# iqn_ail register map
Vendor: Texas Instruments
Registers are 32-bit, read-only, no defined reset value unless marked. A register's access mark holds for its fields unless they carry their own. Offsets are as the file gives them; [hi:lo] are bit positions.

## IQN_AIL (part 4 of 5)
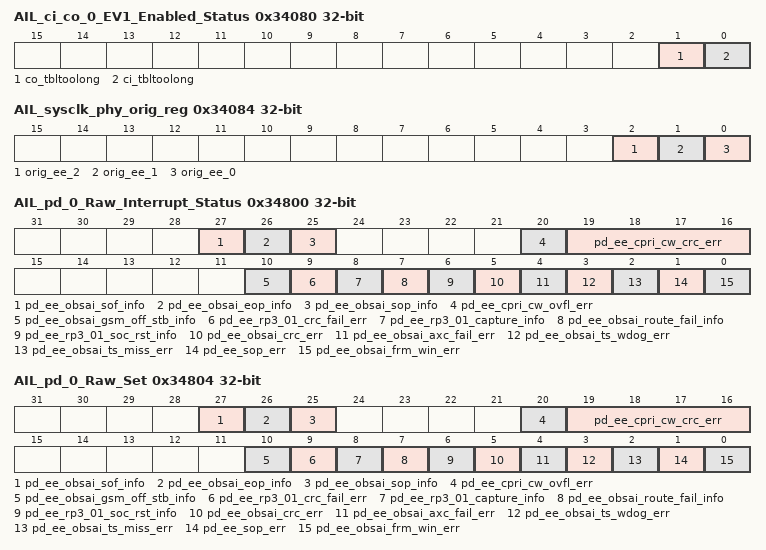
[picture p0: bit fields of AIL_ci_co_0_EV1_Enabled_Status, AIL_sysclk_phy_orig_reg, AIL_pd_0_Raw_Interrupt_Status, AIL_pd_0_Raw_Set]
0x34080 AIL_ci_co_0_EV1_Enabled_Status — (1 of 1, stride 0)
  [1] co_tbltoolong — AND-ed raw_status bits with the corresponding bit in the intr1_status register. Read only.
  [0] ci_tbltoolong — AND-ed raw_status bits with the corresponding bit in the intr1_status register. Read only.
0x34084 AIL_sysclk_phy_orig_reg — (1 of 1, stride 0)
  [2] orig_ee_2 — If set a bit is set in the ci_co_0 register.
  [1] orig_ee_1 — If set a bit is set in the rt_tm_0 register.
  [0] orig_ee_0 — If set a bit is set in the rm_0 register.
0x34800 AIL_pd_0_Raw_Interrupt_Status — (1 of 1, stride 0)
  [27] pd_ee_obsai_sof_info — OBSAI, on any channel, an sof occurred from the PD.
  [26] pd_ee_obsai_eop_info — OBSAI, on any channel, an eop occurred from the PD.
  [25] pd_ee_obsai_sop_info — OBSAI, on any channel, an sop occurred from the PD.
  [20] pd_ee_cpri_cw_ovfl_err — The CPRI CW Fifo for the channel has overflowed, indicating that it was not serviced fast enough.
  [19:16] pd_ee_cpri_cw_crc_err — When CPRI CW CRC checks are enabled, a CRC was received which did not match the calculated CRC. CRC failure could be caused by SERDES bit error
  [10] pd_ee_obsai_gsm_off_stb_info — OBSAI, a gsm off strobe was received for a channel.
  [9] pd_ee_rp3_01_crc_fail_err — OBSAI, a remote rp3-01 message was recieved but the CRC failed for the message.
  [8] pd_ee_rp3_01_capture_info — OBSAI, a remote rp3-01 message was received as determined by the lut table.
  [7] pd_ee_obsai_route_fail_info — OBSAI, a received message failed to match entries for addr and type in the lut table.
  [6] pd_ee_rp3_01_soc_rst_info — OBSAI, received a remote RP3-01 message controlling the entire SOC to perform a HW reset. AIL port will strobe, Must be enabled at higher layers of SOC to perform actual RESET (similar function exists for CPRI, but controlled via PHY_RM)
  [5] pd_ee_obsai_crc_err — OBSAI, ctrl packet crc failure, pkt marked as bad
  [4] pd_ee_obsai_axc_fail_err — OBSAI, unrecoverable ts or wdog error, chan restart. Caused by missing or extra OBSAI messages. (OBSAI time stamp prediction failure)
  [3] pd_ee_obsai_ts_wdog_err — OBSAI, watch dog timed out before chan received OBSAI msg.
  [2] pd_ee_obsai_ts_miss_err — OBSAI, single missing timestamp, sometimes recoverable
  [1] pd_ee_sop_err — Received a second SOP without an EOP in between. Valid for OBSAIpacket types and CPRI 4B/5B encoding (PD_Frame)
  [0] pd_ee_obsai_frm_win_err — OBSAI timestamp failed timing window test. Wrap of the PD_Frame Counters did not predict a Radio Frame Boundary consistent with TS=0 falling within the reception timing window.
0x34804 AIL_pd_0_Raw_Set wo — (1 of 1, stride 0)
  [27] pd_ee_obsai_sof_info — Sets the corresponding bit in the raw_status register when set. Write only, self-clears.
  [26] pd_ee_obsai_eop_info — Sets the corresponding bit in the raw_status register when set. Write only, self-clears.
  [25] pd_ee_obsai_sop_info — Sets the corresponding bit in the raw_status register when set. Write only, self-clears.
  [20] pd_ee_cpri_cw_ovfl_err — Sets the corresponding bit in the raw_status register when set. Write only, self-clears.
  [19:16] pd_ee_cpri_cw_crc_err — Sets the corresponding bit in the raw_status register when set. Write only, self-clears.
  [10] pd_ee_obsai_gsm_off_stb_info — Sets the corresponding bit in the raw_status register when set. Write only, self-clears.
  [9] pd_ee_rp3_01_crc_fail_err — Sets the corresponding bit in the raw_status register when set. Write only, self-clears.
  [8] pd_ee_rp3_01_capture_info — Sets the corresponding bit in the raw_status register when set. Write only, self-clears.
  [7] pd_ee_obsai_route_fail_info — Sets the corresponding bit in the raw_status register when set. Write only, self-clears.
  [6] pd_ee_rp3_01_soc_rst_info — Sets the corresponding bit in the raw_status register when set. Write only, self-clears.
  [5] pd_ee_obsai_crc_err — Sets the corresponding bit in the raw_status register when set. Write only, self-clears.
  [4] pd_ee_obsai_axc_fail_err — Sets the corresponding bit in the raw_status register when set. Write only, self-clears.
  [3] pd_ee_obsai_ts_wdog_err — Sets the corresponding bit in the raw_status register when set. Write only, self-clears.
  [2] pd_ee_obsai_ts_miss_err — Sets the corresponding bit in the raw_status register when set. Write only, self-clears.
  [1] pd_ee_sop_err — Sets the corresponding bit in the raw_status register when set. Write only, self-clears.
  [0] pd_ee_obsai_frm_win_err — Sets the corresponding bit in the raw_status register when set. Write only, self-clears.
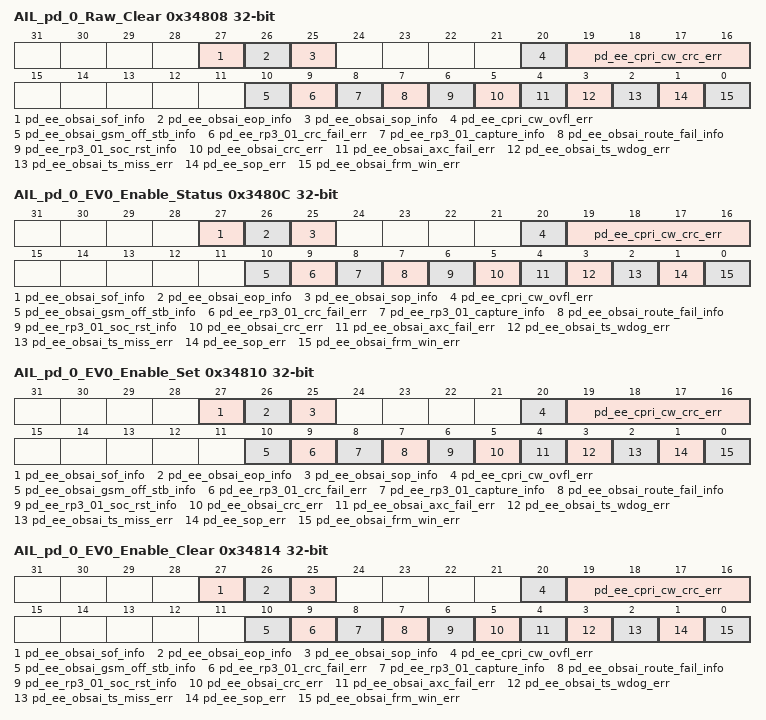
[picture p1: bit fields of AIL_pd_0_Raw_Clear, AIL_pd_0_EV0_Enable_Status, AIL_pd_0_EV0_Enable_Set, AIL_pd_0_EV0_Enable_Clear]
0x34808 AIL_pd_0_Raw_Clear wo — (1 of 1, stride 0)
  [27] pd_ee_obsai_sof_info — Clears the corresponding bit in the raw_status register when set. Write only, self-clears.
  [26] pd_ee_obsai_eop_info — Clears the corresponding bit in the raw_status register when set. Write only, self-clears.
  [25] pd_ee_obsai_sop_info — Clears the corresponding bit in the raw_status register when set. Write only, self-clears.
  [20] pd_ee_cpri_cw_ovfl_err — Clears the corresponding bit in the raw_status register when set. Write only, self-clears.
  [19:16] pd_ee_cpri_cw_crc_err — Clears the corresponding bit in the raw_status register when set. Write only, self-clears.
  [10] pd_ee_obsai_gsm_off_stb_info — Clears the corresponding bit in the raw_status register when set. Write only, self-clears.
  [9] pd_ee_rp3_01_crc_fail_err — Clears the corresponding bit in the raw_status register when set. Write only, self-clears.
  [8] pd_ee_rp3_01_capture_info — Clears the corresponding bit in the raw_status register when set. Write only, self-clears.
  [7] pd_ee_obsai_route_fail_info — Clears the corresponding bit in the raw_status register when set. Write only, self-clears.
  [6] pd_ee_rp3_01_soc_rst_info — Clears the corresponding bit in the raw_status register when set. Write only, self-clears.
  [5] pd_ee_obsai_crc_err — Clears the corresponding bit in the raw_status register when set. Write only, self-clears.
  [4] pd_ee_obsai_axc_fail_err — Clears the corresponding bit in the raw_status register when set. Write only, self-clears.
  [3] pd_ee_obsai_ts_wdog_err — Clears the corresponding bit in the raw_status register when set. Write only, self-clears.
  [2] pd_ee_obsai_ts_miss_err — Clears the corresponding bit in the raw_status register when set. Write only, self-clears.
  [1] pd_ee_sop_err — Clears the corresponding bit in the raw_status register when set. Write only, self-clears.
  [0] pd_ee_obsai_frm_win_err — Clears the corresponding bit in the raw_status register when set. Write only, self-clears.
0x3480C AIL_pd_0_EV0_Enable_Status — (1 of 1, stride 0)
  [27] pd_ee_obsai_sof_info — When set allows the corresponding bit in the raw_status register to generate the intr_sts interrupt. Read only.
  [26] pd_ee_obsai_eop_info — When set allows the corresponding bit in the raw_status register to generate the intr_sts interrupt. Read only.
  [25] pd_ee_obsai_sop_info — When set allows the corresponding bit in the raw_status register to generate the intr_sts interrupt. Read only.
  [20] pd_ee_cpri_cw_ovfl_err — When set allows the corresponding bit in the raw_status register to generate the intr_sts interrupt. Read only.
  [19:16] pd_ee_cpri_cw_crc_err — When set allows the corresponding bit in the raw_status register to generate the intr_sts interrupt. Read only.
  [10] pd_ee_obsai_gsm_off_stb_info — When set allows the corresponding bit in the raw_status register to generate the intr_sts interrupt. Read only.
  [9] pd_ee_rp3_01_crc_fail_err — When set allows the corresponding bit in the raw_status register to generate the intr_sts interrupt. Read only.
  [8] pd_ee_rp3_01_capture_info — When set allows the corresponding bit in the raw_status register to generate the intr_sts interrupt. Read only.
  [7] pd_ee_obsai_route_fail_info — When set allows the corresponding bit in the raw_status register to generate the intr_sts interrupt. Read only.
  [6] pd_ee_rp3_01_soc_rst_info — When set allows the corresponding bit in the raw_status register to generate the intr_sts interrupt. Read only.
  [5] pd_ee_obsai_crc_err — When set allows the corresponding bit in the raw_status register to generate the intr_sts interrupt. Read only.
  [4] pd_ee_obsai_axc_fail_err — When set allows the corresponding bit in the raw_status register to generate the intr_sts interrupt. Read only.
  [3] pd_ee_obsai_ts_wdog_err — When set allows the corresponding bit in the raw_status register to generate the intr_sts interrupt. Read only.
  [2] pd_ee_obsai_ts_miss_err — When set allows the corresponding bit in the raw_status register to generate the intr_sts interrupt. Read only.
  [1] pd_ee_sop_err — When set allows the corresponding bit in the raw_status register to generate the intr_sts interrupt. Read only.
  [0] pd_ee_obsai_frm_win_err — When set allows the corresponding bit in the raw_status register to generate the intr_sts interrupt. Read only.
0x34810 AIL_pd_0_EV0_Enable_Set wo — (1 of 1, stride 0)
  [27] pd_ee_obsai_sof_info — Sets the corresponding bit in the enable register when set. Write only, self-clears.
  [26] pd_ee_obsai_eop_info — Sets the corresponding bit in the enable register when set. Write only, self-clears.
  [25] pd_ee_obsai_sop_info — Sets the corresponding bit in the enable register when set. Write only, self-clears.
  [20] pd_ee_cpri_cw_ovfl_err — Sets the corresponding bit in the enable register when set. Write only, self-clears.
  [19:16] pd_ee_cpri_cw_crc_err — Sets the corresponding bit in the enable register when set. Write only, self-clears.
  [10] pd_ee_obsai_gsm_off_stb_info — Sets the corresponding bit in the enable register when set. Write only, self-clears.
  [9] pd_ee_rp3_01_crc_fail_err — Sets the corresponding bit in the enable register when set. Write only, self-clears.
  [8] pd_ee_rp3_01_capture_info — Sets the corresponding bit in the enable register when set. Write only, self-clears.
  [7] pd_ee_obsai_route_fail_info — Sets the corresponding bit in the enable register when set. Write only, self-clears.
  [6] pd_ee_rp3_01_soc_rst_info — Sets the corresponding bit in the enable register when set. Write only, self-clears.
  [5] pd_ee_obsai_crc_err — Sets the corresponding bit in the enable register when set. Write only, self-clears.
  [4] pd_ee_obsai_axc_fail_err — Sets the corresponding bit in the enable register when set. Write only, self-clears.
  [3] pd_ee_obsai_ts_wdog_err — Sets the corresponding bit in the enable register when set. Write only, self-clears.
  [2] pd_ee_obsai_ts_miss_err — Sets the corresponding bit in the enable register when set. Write only, self-clears.
  [1] pd_ee_sop_err — Sets the corresponding bit in the enable register when set. Write only, self-clears.
  [0] pd_ee_obsai_frm_win_err — Sets the corresponding bit in the enable register when set. Write only, self-clears.
0x34814 AIL_pd_0_EV0_Enable_Clear wo — (1 of 1, stride 0)
  [27] pd_ee_obsai_sof_info — Clears the corresponding bit in the enable register when set. Write only, self-clears.
  [26] pd_ee_obsai_eop_info — Clears the corresponding bit in the enable register when set. Write only, self-clears.
  [25] pd_ee_obsai_sop_info — Clears the corresponding bit in the enable register when set. Write only, self-clears.
  [20] pd_ee_cpri_cw_ovfl_err — Clears the corresponding bit in the enable register when set. Write only, self-clears.
  [19:16] pd_ee_cpri_cw_crc_err — Clears the corresponding bit in the enable register when set. Write only, self-clears.
  [10] pd_ee_obsai_gsm_off_stb_info — Clears the corresponding bit in the enable register when set. Write only, self-clears.
  [9] pd_ee_rp3_01_crc_fail_err — Clears the corresponding bit in the enable register when set. Write only, self-clears.
  [8] pd_ee_rp3_01_capture_info — Clears the corresponding bit in the enable register when set. Write only, self-clears.
  [7] pd_ee_obsai_route_fail_info — Clears the corresponding bit in the enable register when set. Write only, self-clears.
  [6] pd_ee_rp3_01_soc_rst_info — Clears the corresponding bit in the enable register when set. Write only, self-clears.
  [5] pd_ee_obsai_crc_err — Clears the corresponding bit in the enable register when set. Write only, self-clears.
  [4] pd_ee_obsai_axc_fail_err — Clears the corresponding bit in the enable register when set. Write only, self-clears.
  [3] pd_ee_obsai_ts_wdog_err — Clears the corresponding bit in the enable register when set. Write only, self-clears.
  [2] pd_ee_obsai_ts_miss_err — Clears the corresponding bit in the enable register when set. Write only, self-clears.
  [1] pd_ee_sop_err — Clears the corresponding bit in the enable register when set. Write only, self-clears.
  [0] pd_ee_obsai_frm_win_err — Clears the corresponding bit in the enable register when set. Write only, self-clears.
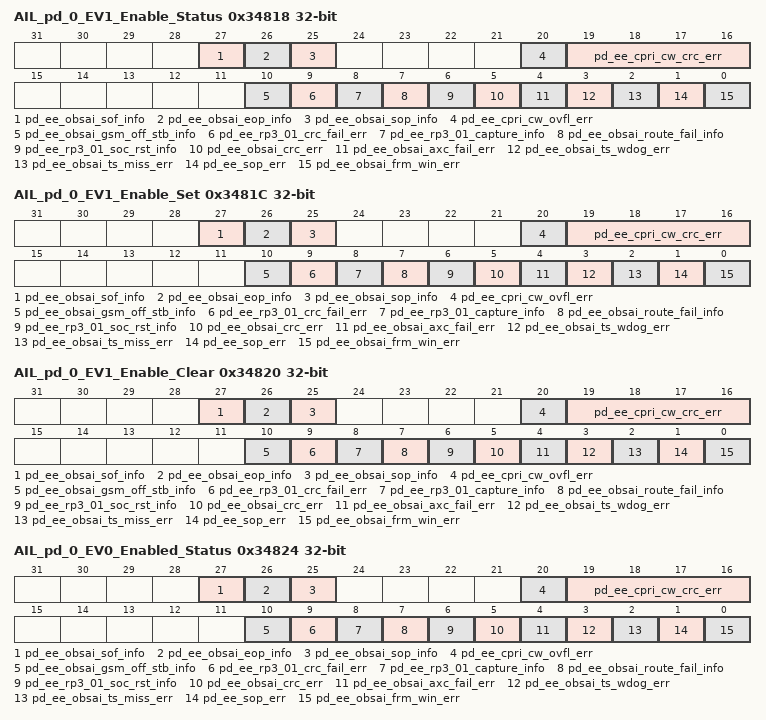
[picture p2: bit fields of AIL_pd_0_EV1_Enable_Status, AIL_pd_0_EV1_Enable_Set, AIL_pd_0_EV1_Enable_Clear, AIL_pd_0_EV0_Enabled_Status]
0x34818 AIL_pd_0_EV1_Enable_Status — (1 of 1, stride 0)
  [27] pd_ee_obsai_sof_info — When set allows the corresponding bit in the raw_status register to generate the intr1_sts interrupt. Read only.
  [26] pd_ee_obsai_eop_info — When set allows the corresponding bit in the raw_status register to generate the intr1_sts interrupt. Read only.
  [25] pd_ee_obsai_sop_info — When set allows the corresponding bit in the raw_status register to generate the intr1_sts interrupt. Read only.
  [20] pd_ee_cpri_cw_ovfl_err — When set allows the corresponding bit in the raw_status register to generate the intr1_sts interrupt. Read only.
  [19:16] pd_ee_cpri_cw_crc_err — When set allows the corresponding bit in the raw_status register to generate the intr1_sts interrupt. Read only.
  [10] pd_ee_obsai_gsm_off_stb_info — When set allows the corresponding bit in the raw_status register to generate the intr1_sts interrupt. Read only.
  [9] pd_ee_rp3_01_crc_fail_err — When set allows the corresponding bit in the raw_status register to generate the intr1_sts interrupt. Read only.
  [8] pd_ee_rp3_01_capture_info — When set allows the corresponding bit in the raw_status register to generate the intr1_sts interrupt. Read only.
  [7] pd_ee_obsai_route_fail_info — When set allows the corresponding bit in the raw_status register to generate the intr1_sts interrupt. Read only.
  [6] pd_ee_rp3_01_soc_rst_info — When set allows the corresponding bit in the raw_status register to generate the intr1_sts interrupt. Read only.
  [5] pd_ee_obsai_crc_err — When set allows the corresponding bit in the raw_status register to generate the intr1_sts interrupt. Read only.
  [4] pd_ee_obsai_axc_fail_err — When set allows the corresponding bit in the raw_status register to generate the intr1_sts interrupt. Read only.
  [3] pd_ee_obsai_ts_wdog_err — When set allows the corresponding bit in the raw_status register to generate the intr1_sts interrupt. Read only.
  [2] pd_ee_obsai_ts_miss_err — When set allows the corresponding bit in the raw_status register to generate the intr1_sts interrupt. Read only.
  [1] pd_ee_sop_err — When set allows the corresponding bit in the raw_status register to generate the intr1_sts interrupt. Read only.
  [0] pd_ee_obsai_frm_win_err — When set allows the corresponding bit in the raw_status register to generate the intr1_sts interrupt. Read only.
0x3481C AIL_pd_0_EV1_Enable_Set wo — (1 of 1, stride 0)
  [27] pd_ee_obsai_sof_info — Sets the corresponding bit in the intr1_status register when set. Write only, self-clears.
  [26] pd_ee_obsai_eop_info — Sets the corresponding bit in the intr1_status register when set. Write only, self-clears.
  [25] pd_ee_obsai_sop_info — Sets the corresponding bit in the intr1_status register when set. Write only, self-clears.
  [20] pd_ee_cpri_cw_ovfl_err — Sets the corresponding bit in the intr1_status register when set. Write only, self-clears.
  [19:16] pd_ee_cpri_cw_crc_err — Sets the corresponding bit in the intr1_status register when set. Write only, self-clears.
  [10] pd_ee_obsai_gsm_off_stb_info — Sets the corresponding bit in the intr1_status register when set. Write only, self-clears.
  [9] pd_ee_rp3_01_crc_fail_err — Sets the corresponding bit in the intr1_status register when set. Write only, self-clears.
  [8] pd_ee_rp3_01_capture_info — Sets the corresponding bit in the intr1_status register when set. Write only, self-clears.
  [7] pd_ee_obsai_route_fail_info — Sets the corresponding bit in the intr1_status register when set. Write only, self-clears.
  [6] pd_ee_rp3_01_soc_rst_info — Sets the corresponding bit in the intr1_status register when set. Write only, self-clears.
  [5] pd_ee_obsai_crc_err — Sets the corresponding bit in the intr1_status register when set. Write only, self-clears.
  [4] pd_ee_obsai_axc_fail_err — Sets the corresponding bit in the intr1_status register when set. Write only, self-clears.
  [3] pd_ee_obsai_ts_wdog_err — Sets the corresponding bit in the intr1_status register when set. Write only, self-clears.
  [2] pd_ee_obsai_ts_miss_err — Sets the corresponding bit in the intr1_status register when set. Write only, self-clears.
  [1] pd_ee_sop_err — Sets the corresponding bit in the intr1_status register when set. Write only, self-clears.
  [0] pd_ee_obsai_frm_win_err — Sets the corresponding bit in the intr1_status register when set. Write only, self-clears.
0x34820 AIL_pd_0_EV1_Enable_Clear wo — (1 of 1, stride 0)
  [27] pd_ee_obsai_sof_info — Clears the corresponding bit in the intr1_status register when set. Write only, self-clears.
  [26] pd_ee_obsai_eop_info — Clears the corresponding bit in the intr1_status register when set. Write only, self-clears.
  [25] pd_ee_obsai_sop_info — Clears the corresponding bit in the intr1_status register when set. Write only, self-clears.
  [20] pd_ee_cpri_cw_ovfl_err — Clears the corresponding bit in the intr1_status register when set. Write only, self-clears.
  [19:16] pd_ee_cpri_cw_crc_err — Clears the corresponding bit in the intr1_status register when set. Write only, self-clears.
  [10] pd_ee_obsai_gsm_off_stb_info — Clears the corresponding bit in the intr1_status register when set. Write only, self-clears.
  [9] pd_ee_rp3_01_crc_fail_err — Clears the corresponding bit in the intr1_status register when set. Write only, self-clears.
  [8] pd_ee_rp3_01_capture_info — Clears the corresponding bit in the intr1_status register when set. Write only, self-clears.
  [7] pd_ee_obsai_route_fail_info — Clears the corresponding bit in the intr1_status register when set. Write only, self-clears.
  [6] pd_ee_rp3_01_soc_rst_info — Clears the corresponding bit in the intr1_status register when set. Write only, self-clears.
  [5] pd_ee_obsai_crc_err — Clears the corresponding bit in the intr1_status register when set. Write only, self-clears.
  [4] pd_ee_obsai_axc_fail_err — Clears the corresponding bit in the intr1_status register when set. Write only, self-clears.
  [3] pd_ee_obsai_ts_wdog_err — Clears the corresponding bit in the intr1_status register when set. Write only, self-clears.
  [2] pd_ee_obsai_ts_miss_err — Clears the corresponding bit in the intr1_status register when set. Write only, self-clears.
  [1] pd_ee_sop_err — Clears the corresponding bit in the intr1_status register when set. Write only, self-clears.
  [0] pd_ee_obsai_frm_win_err — Clears the corresponding bit in the intr1_status register when set. Write only, self-clears.
0x34824 AIL_pd_0_EV0_Enabled_Status — (1 of 1, stride 0)
  [27] pd_ee_obsai_sof_info — AND-ed raw_status bits with the corresponding bit in the enable_status register. Read only.
  [26] pd_ee_obsai_eop_info — AND-ed raw_status bits with the corresponding bit in the enable_status register. Read only.
  [25] pd_ee_obsai_sop_info — AND-ed raw_status bits with the corresponding bit in the enable_status register. Read only.
  [20] pd_ee_cpri_cw_ovfl_err — AND-ed raw_status bits with the corresponding bit in the enable_status register. Read only.
  [19:16] pd_ee_cpri_cw_crc_err — AND-ed raw_status bits with the corresponding bit in the enable_status register. Read only.
  [10] pd_ee_obsai_gsm_off_stb_info — AND-ed raw_status bits with the corresponding bit in the enable_status register. Read only.
  [9] pd_ee_rp3_01_crc_fail_err — AND-ed raw_status bits with the corresponding bit in the enable_status register. Read only.
  [8] pd_ee_rp3_01_capture_info — AND-ed raw_status bits with the corresponding bit in the enable_status register. Read only.
  [7] pd_ee_obsai_route_fail_info — AND-ed raw_status bits with the corresponding bit in the enable_status register. Read only.
  [6] pd_ee_rp3_01_soc_rst_info — AND-ed raw_status bits with the corresponding bit in the enable_status register. Read only.
  [5] pd_ee_obsai_crc_err — AND-ed raw_status bits with the corresponding bit in the enable_status register. Read only.
  [4] pd_ee_obsai_axc_fail_err — AND-ed raw_status bits with the corresponding bit in the enable_status register. Read only.
  [3] pd_ee_obsai_ts_wdog_err — AND-ed raw_status bits with the corresponding bit in the enable_status register. Read only.
  [2] pd_ee_obsai_ts_miss_err — AND-ed raw_status bits with the corresponding bit in the enable_status register. Read only.
  [1] pd_ee_sop_err — AND-ed raw_status bits with the corresponding bit in the enable_status register. Read only.
  [0] pd_ee_obsai_frm_win_err — AND-ed raw_status bits with the corresponding bit in the enable_status register. Read only.
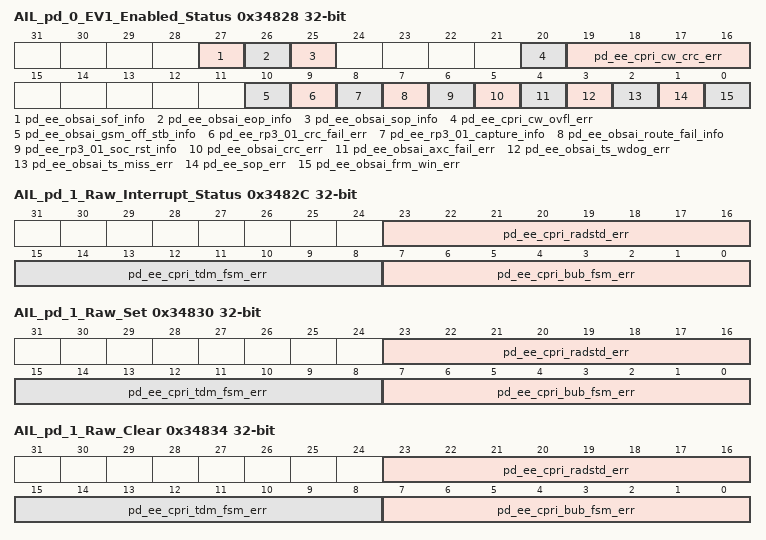
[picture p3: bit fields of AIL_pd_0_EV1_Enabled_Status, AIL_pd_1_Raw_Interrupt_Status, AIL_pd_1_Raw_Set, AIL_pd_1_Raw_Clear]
0x34828 AIL_pd_0_EV1_Enabled_Status — (1 of 1, stride 0)
  [27] pd_ee_obsai_sof_info — AND-ed raw_status bits with the corresponding bit in the intr1_status register. Read only.
  [26] pd_ee_obsai_eop_info — AND-ed raw_status bits with the corresponding bit in the intr1_status register. Read only.
  [25] pd_ee_obsai_sop_info — AND-ed raw_status bits with the corresponding bit in the intr1_status register. Read only.
  [20] pd_ee_cpri_cw_ovfl_err — AND-ed raw_status bits with the corresponding bit in the intr1_status register. Read only.
  [19:16] pd_ee_cpri_cw_crc_err — AND-ed raw_status bits with the corresponding bit in the intr1_status register. Read only.
  [10] pd_ee_obsai_gsm_off_stb_info — AND-ed raw_status bits with the corresponding bit in the intr1_status register. Read only.
  [9] pd_ee_rp3_01_crc_fail_err — AND-ed raw_status bits with the corresponding bit in the intr1_status register. Read only.
  [8] pd_ee_rp3_01_capture_info — AND-ed raw_status bits with the corresponding bit in the intr1_status register. Read only.
  [7] pd_ee_obsai_route_fail_info — AND-ed raw_status bits with the corresponding bit in the intr1_status register. Read only.
  [6] pd_ee_rp3_01_soc_rst_info — AND-ed raw_status bits with the corresponding bit in the intr1_status register. Read only.
  [5] pd_ee_obsai_crc_err — AND-ed raw_status bits with the corresponding bit in the intr1_status register. Read only.
  [4] pd_ee_obsai_axc_fail_err — AND-ed raw_status bits with the corresponding bit in the intr1_status register. Read only.
  [3] pd_ee_obsai_ts_wdog_err — AND-ed raw_status bits with the corresponding bit in the intr1_status register. Read only.
  [2] pd_ee_obsai_ts_miss_err — AND-ed raw_status bits with the corresponding bit in the intr1_status register. Read only.
  [1] pd_ee_sop_err — AND-ed raw_status bits with the corresponding bit in the intr1_status register. Read only.
  [0] pd_ee_obsai_frm_win_err — AND-ed raw_status bits with the corresponding bit in the intr1_status register. Read only.
0x3482C AIL_pd_1_Raw_Interrupt_Status — (1 of 1, stride 0)
  [23:16] pd_ee_cpri_radstd_err — The radio standard framing FSM did not wrap naturally back to zero on a 10ms boundary (indicated by hyperframe and basic frame offset relative to PHY frame boundary). For GSM or some WiMax radio standards without 10ms framing, this error should be
  [15:8] pd_ee_cpri_tdm_fsm_err — CPRI Channel TDM did not wrap back to start position prior to end of an iteration window (few GSM cases will legally cause this EE) Mostly likely cause is incorrect programming of TDM and Bubble insertion parameters.
  [7:0] pd_ee_cpri_bub_fsm_err — The bubble FSM did not wrap back to zero on a radio frame boundary. This is likely a programming error. In GSM, a radio frame boundary is 60ms.
0x34830 AIL_pd_1_Raw_Set wo — (1 of 1, stride 0)
  [23:16] pd_ee_cpri_radstd_err — Sets the corresponding bit in the raw_status register when set. Write only, self-clears.
  [15:8] pd_ee_cpri_tdm_fsm_err — Sets the corresponding bit in the raw_status register when set. Write only, self-clears.
  [7:0] pd_ee_cpri_bub_fsm_err — Sets the corresponding bit in the raw_status register when set. Write only, self-clears.
0x34834 AIL_pd_1_Raw_Clear wo — (1 of 1, stride 0)
  [23:16] pd_ee_cpri_radstd_err — Clears the corresponding bit in the raw_status register when set. Write only, self-clears.
  [15:8] pd_ee_cpri_tdm_fsm_err — Clears the corresponding bit in the raw_status register when set. Write only, self-clears.
  [7:0] pd_ee_cpri_bub_fsm_err — Clears the corresponding bit in the raw_status register when set. Write only, self-clears.
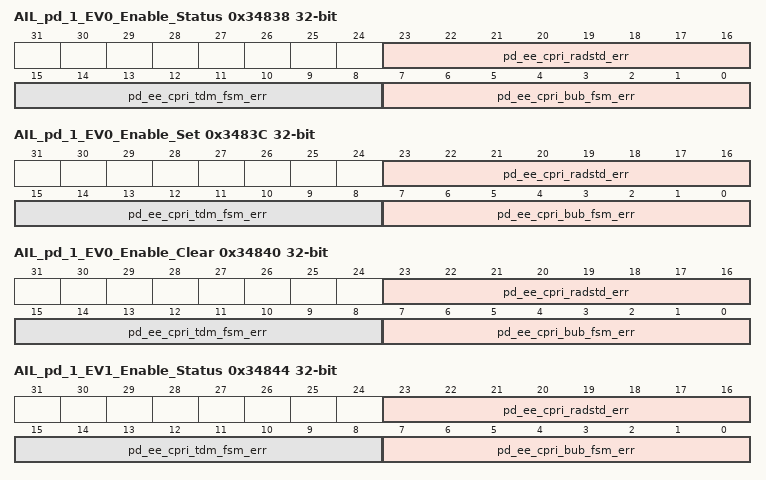
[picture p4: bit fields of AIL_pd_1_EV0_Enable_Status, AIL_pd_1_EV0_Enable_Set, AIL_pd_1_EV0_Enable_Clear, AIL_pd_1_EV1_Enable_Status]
0x34838 AIL_pd_1_EV0_Enable_Status — (1 of 1, stride 0)
  [23:16] pd_ee_cpri_radstd_err — When set allows the corresponding bit in the raw_status register to generate the intr_sts interrupt. Read only.
  [15:8] pd_ee_cpri_tdm_fsm_err — When set allows the corresponding bit in the raw_status register to generate the intr_sts interrupt. Read only.
  [7:0] pd_ee_cpri_bub_fsm_err — When set allows the corresponding bit in the raw_status register to generate the intr_sts interrupt. Read only.
0x3483C AIL_pd_1_EV0_Enable_Set wo — (1 of 1, stride 0)
  [23:16] pd_ee_cpri_radstd_err — Sets the corresponding bit in the enable register when set. Write only, self-clears.
  [15:8] pd_ee_cpri_tdm_fsm_err — Sets the corresponding bit in the enable register when set. Write only, self-clears.
  [7:0] pd_ee_cpri_bub_fsm_err — Sets the corresponding bit in the enable register when set. Write only, self-clears.
0x34840 AIL_pd_1_EV0_Enable_Clear wo — (1 of 1, stride 0)
  [23:16] pd_ee_cpri_radstd_err — Clears the corresponding bit in the enable register when set. Write only, self-clears.
  [15:8] pd_ee_cpri_tdm_fsm_err — Clears the corresponding bit in the enable register when set. Write only, self-clears.
  [7:0] pd_ee_cpri_bub_fsm_err — Clears the corresponding bit in the enable register when set. Write only, self-clears.
0x34844 AIL_pd_1_EV1_Enable_Status — (1 of 1, stride 0)
  [23:16] pd_ee_cpri_radstd_err — When set allows the corresponding bit in the raw_status register to generate the intr1_sts interrupt. Read only.
  [15:8] pd_ee_cpri_tdm_fsm_err — When set allows the corresponding bit in the raw_status register to generate the intr1_sts interrupt. Read only.
  [7:0] pd_ee_cpri_bub_fsm_err — When set allows the corresponding bit in the raw_status register to generate the intr1_sts interrupt. Read only.
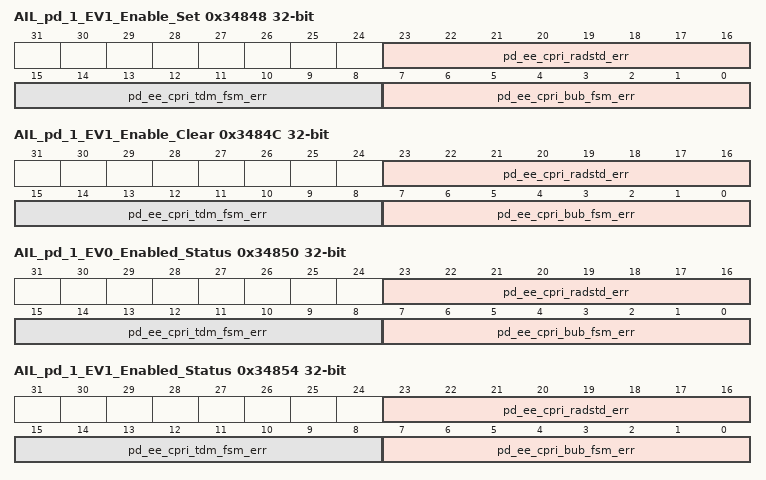
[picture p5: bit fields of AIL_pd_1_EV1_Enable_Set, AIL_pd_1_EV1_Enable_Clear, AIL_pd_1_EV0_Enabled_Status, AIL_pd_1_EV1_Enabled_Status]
0x34848 AIL_pd_1_EV1_Enable_Set wo — (1 of 1, stride 0)
  [23:16] pd_ee_cpri_radstd_err — Sets the corresponding bit in the intr1_status register when set. Write only, self-clears.
  [15:8] pd_ee_cpri_tdm_fsm_err — Sets the corresponding bit in the intr1_status register when set. Write only, self-clears.
  [7:0] pd_ee_cpri_bub_fsm_err — Sets the corresponding bit in the intr1_status register when set. Write only, self-clears.
0x3484C AIL_pd_1_EV1_Enable_Clear wo — (1 of 1, stride 0)
  [23:16] pd_ee_cpri_radstd_err — Clears the corresponding bit in the intr1_status register when set. Write only, self-clears.
  [15:8] pd_ee_cpri_tdm_fsm_err — Clears the corresponding bit in the intr1_status register when set. Write only, self-clears.
  [7:0] pd_ee_cpri_bub_fsm_err — Clears the corresponding bit in the intr1_status register when set. Write only, self-clears.
0x34850 AIL_pd_1_EV0_Enabled_Status — (1 of 1, stride 0)
  [23:16] pd_ee_cpri_radstd_err — AND-ed raw_status bits with the corresponding bit in the enable_status register. Read only.
  [15:8] pd_ee_cpri_tdm_fsm_err — AND-ed raw_status bits with the corresponding bit in the enable_status register. Read only.
  [7:0] pd_ee_cpri_bub_fsm_err — AND-ed raw_status bits with the corresponding bit in the enable_status register. Read only.
0x34854 AIL_pd_1_EV1_Enabled_Status — (1 of 1, stride 0)
  [23:16] pd_ee_cpri_radstd_err — AND-ed raw_status bits with the corresponding bit in the intr1_status register. Read only.
  [15:8] pd_ee_cpri_tdm_fsm_err — AND-ed raw_status bits with the corresponding bit in the intr1_status register. Read only.
  [7:0] pd_ee_cpri_bub_fsm_err — AND-ed raw_status bits with the corresponding bit in the intr1_status register. Read only.
0x34858 AIL_pd_2_0_Raw_Interrupt_Status access not given — (1 of 1, stride 0)
0x3485C AIL_pd_2_0_Raw_Set access not given — (1 of 1, stride 0)
0x34860 AIL_pd_2_0_Raw_Clear access not given — (1 of 1, stride 0)
0x34864 AIL_pd_2_0_EV0_Enable_Status access not given — (1 of 1, stride 0)
0x34868 AIL_pd_2_0_EV0_Enable_Set access not given — (1 of 1, stride 0)
0x3486C AIL_pd_2_0_EV0_Enable_Clear access not given — (1 of 1, stride 0)
0x34870 AIL_pd_2_0_EV1_Enable_Status access not given — (1 of 1, stride 0)
0x34874 AIL_pd_2_0_EV1_Enable_Set access not given — (1 of 1, stride 0)
0x34878 AIL_pd_2_0_EV1_Enable_Clear access not given — (1 of 1, stride 0)
0x3487C AIL_pd_2_0_EV0_Enabled_Status access not given — (1 of 1, stride 0)
0x34880 AIL_pd_2_0_EV1_Enabled_Status access not given — (1 of 1, stride 0)
0x34884 AIL_pd_2_1_Raw_Interrupt_Status access not given — (1 of 1, stride 0)
0x34888 AIL_pd_2_1_Raw_Set access not given — (1 of 1, stride 0)
0x3488C AIL_pd_2_1_Raw_Clear access not given — (1 of 1, stride 0)
0x34890 AIL_pd_2_1_EV0_Enable_Status access not given — (1 of 1, stride 0)
0x34894 AIL_pd_2_1_EV0_Enable_Set access not given — (1 of 1, stride 0)
0x34898 AIL_pd_2_1_EV0_Enable_Clear access not given — (1 of 1, stride 0)
0x3489C AIL_pd_2_1_EV1_Enable_Status access not given — (1 of 1, stride 0)
0x348A0 AIL_pd_2_1_EV1_Enable_Set access not given — (1 of 1, stride 0)
0x348A4 AIL_pd_2_1_EV1_Enable_Clear access not given — (1 of 1, stride 0)
0x348A8 AIL_pd_2_1_EV0_Enabled_Status access not given — (1 of 1, stride 0)
0x348AC AIL_pd_2_1_EV1_Enabled_Status access not given — (1 of 1, stride 0)
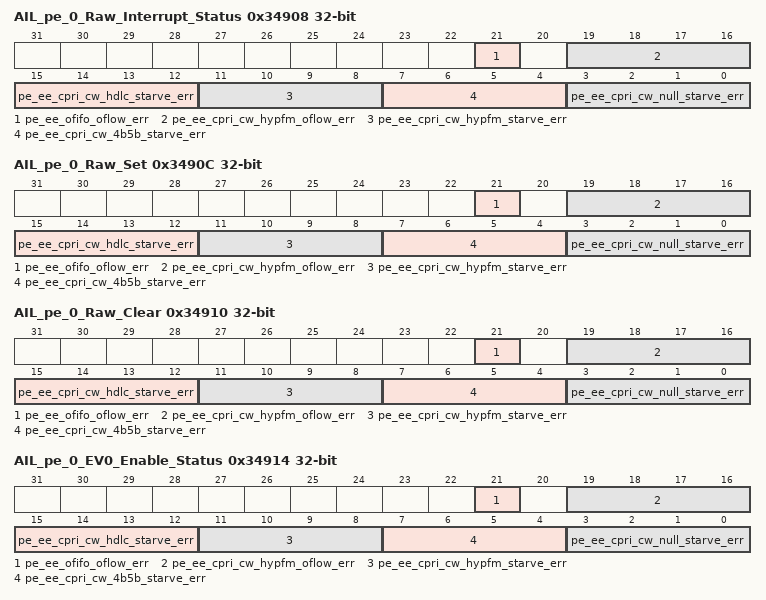
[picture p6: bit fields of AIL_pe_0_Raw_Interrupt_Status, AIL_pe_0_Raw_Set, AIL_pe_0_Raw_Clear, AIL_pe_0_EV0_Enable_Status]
0x34908 AIL_pe_0_Raw_Interrupt_Status — (1 of 1, stride 0)
  [21] pe_ee_ofifo_oflow_err — The PE-to-RT FIFO overflowed. Suspected cause is PE_STB from uAT is too early or RT has been programmed to disregard PE traffic.
  [19:16] pe_ee_cpri_cw_hypfm_oflow_err — Indicates a Hyperframe packet did not complete before the hyperframe boundary.
  [15:12] pe_ee_cpri_cw_hdlc_starve_err — Indicates there was no data available for transfer while in an active packet state
  [11:8] pe_ee_cpri_cw_hypfm_starve_err — Indicates there was no data available for transfer while in an active packet state
  [7:4] pe_ee_cpri_cw_4b5b_starve_err — Indicates there was no data available for transfer while in an active packet state
  [3:0] pe_ee_cpri_cw_null_starve_err — Indicates there was no data available for transfer while in an active packet state
0x3490C AIL_pe_0_Raw_Set wo — (1 of 1, stride 0)
  [21] pe_ee_ofifo_oflow_err — Sets the corresponding bit in the raw_status register when set. Write only, self-clears.
  [19:16] pe_ee_cpri_cw_hypfm_oflow_err — Sets the corresponding bit in the raw_status register when set. Write only, self-clears.
  [15:12] pe_ee_cpri_cw_hdlc_starve_err — Sets the corresponding bit in the raw_status register when set. Write only, self-clears.
  [11:8] pe_ee_cpri_cw_hypfm_starve_err — Sets the corresponding bit in the raw_status register when set. Write only, self-clears.
  [7:4] pe_ee_cpri_cw_4b5b_starve_err — Sets the corresponding bit in the raw_status register when set. Write only, self-clears.
  [3:0] pe_ee_cpri_cw_null_starve_err — Sets the corresponding bit in the raw_status register when set. Write only, self-clears.
0x34910 AIL_pe_0_Raw_Clear wo — (1 of 1, stride 0)
  [21] pe_ee_ofifo_oflow_err — Clears the corresponding bit in the raw_status register when set. Write only, self-clears.
  [19:16] pe_ee_cpri_cw_hypfm_oflow_err — Clears the corresponding bit in the raw_status register when set. Write only, self-clears.
  [15:12] pe_ee_cpri_cw_hdlc_starve_err — Clears the corresponding bit in the raw_status register when set. Write only, self-clears.
  [11:8] pe_ee_cpri_cw_hypfm_starve_err — Clears the corresponding bit in the raw_status register when set. Write only, self-clears.
  [7:4] pe_ee_cpri_cw_4b5b_starve_err — Clears the corresponding bit in the raw_status register when set. Write only, self-clears.
  [3:0] pe_ee_cpri_cw_null_starve_err — Clears the corresponding bit in the raw_status register when set. Write only, self-clears.
0x34914 AIL_pe_0_EV0_Enable_Status — (1 of 1, stride 0)
  [21] pe_ee_ofifo_oflow_err — When set allows the corresponding bit in the raw_status register to generate the intr_sts interrupt. Read only.
  [19:16] pe_ee_cpri_cw_hypfm_oflow_err — When set allows the corresponding bit in the raw_status register to generate the intr_sts interrupt. Read only.
  [15:12] pe_ee_cpri_cw_hdlc_starve_err — When set allows the corresponding bit in the raw_status register to generate the intr_sts interrupt. Read only.
  [11:8] pe_ee_cpri_cw_hypfm_starve_err — When set allows the corresponding bit in the raw_status register to generate the intr_sts interrupt. Read only.
  [7:4] pe_ee_cpri_cw_4b5b_starve_err — When set allows the corresponding bit in the raw_status register to generate the intr_sts interrupt. Read only.
  [3:0] pe_ee_cpri_cw_null_starve_err — When set allows the corresponding bit in the raw_status register to generate the intr_sts interrupt. Read only.
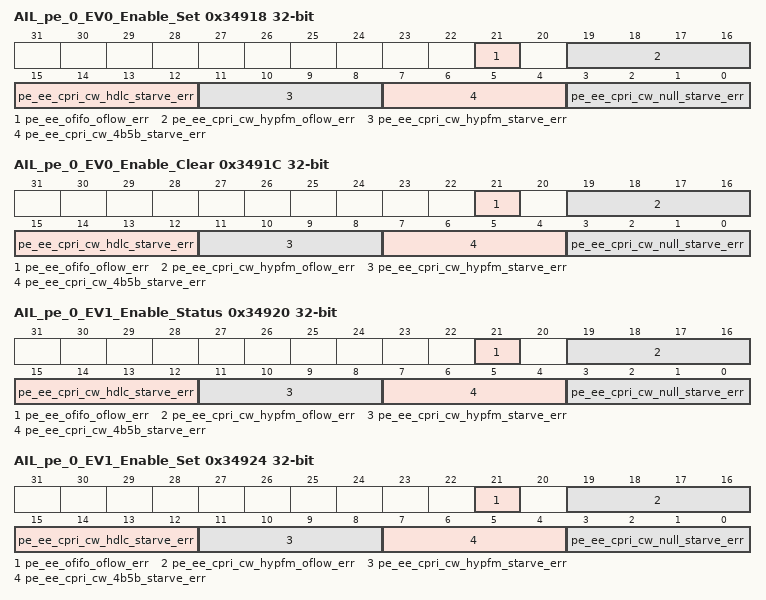
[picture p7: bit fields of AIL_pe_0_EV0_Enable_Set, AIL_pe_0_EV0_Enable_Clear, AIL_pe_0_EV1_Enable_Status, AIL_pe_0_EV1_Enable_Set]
0x34918 AIL_pe_0_EV0_Enable_Set wo — (1 of 1, stride 0)
  [21] pe_ee_ofifo_oflow_err — Sets the corresponding bit in the enable register when set. Write only, self-clears.
  [19:16] pe_ee_cpri_cw_hypfm_oflow_err — Sets the corresponding bit in the enable register when set. Write only, self-clears.
  [15:12] pe_ee_cpri_cw_hdlc_starve_err — Sets the corresponding bit in the enable register when set. Write only, self-clears.
  [11:8] pe_ee_cpri_cw_hypfm_starve_err — Sets the corresponding bit in the enable register when set. Write only, self-clears.
  [7:4] pe_ee_cpri_cw_4b5b_starve_err — Sets the corresponding bit in the enable register when set. Write only, self-clears.
  [3:0] pe_ee_cpri_cw_null_starve_err — Sets the corresponding bit in the enable register when set. Write only, self-clears.
0x3491C AIL_pe_0_EV0_Enable_Clear wo — (1 of 1, stride 0)
  [21] pe_ee_ofifo_oflow_err — Clears the corresponding bit in the enable register when set. Write only, self-clears.
  [19:16] pe_ee_cpri_cw_hypfm_oflow_err — Clears the corresponding bit in the enable register when set. Write only, self-clears.
  [15:12] pe_ee_cpri_cw_hdlc_starve_err — Clears the corresponding bit in the enable register when set. Write only, self-clears.
  [11:8] pe_ee_cpri_cw_hypfm_starve_err — Clears the corresponding bit in the enable register when set. Write only, self-clears.
  [7:4] pe_ee_cpri_cw_4b5b_starve_err — Clears the corresponding bit in the enable register when set. Write only, self-clears.
  [3:0] pe_ee_cpri_cw_null_starve_err — Clears the corresponding bit in the enable register when set. Write only, self-clears.
0x34920 AIL_pe_0_EV1_Enable_Status — (1 of 1, stride 0)
  [21] pe_ee_ofifo_oflow_err — When set allows the corresponding bit in the raw_status register to generate the intr1_sts interrupt. Read only.
  [19:16] pe_ee_cpri_cw_hypfm_oflow_err — When set allows the corresponding bit in the raw_status register to generate the intr1_sts interrupt. Read only.
  [15:12] pe_ee_cpri_cw_hdlc_starve_err — When set allows the corresponding bit in the raw_status register to generate the intr1_sts interrupt. Read only.
  [11:8] pe_ee_cpri_cw_hypfm_starve_err — When set allows the corresponding bit in the raw_status register to generate the intr1_sts interrupt. Read only.
  [7:4] pe_ee_cpri_cw_4b5b_starve_err — When set allows the corresponding bit in the raw_status register to generate the intr1_sts interrupt. Read only.
  [3:0] pe_ee_cpri_cw_null_starve_err — When set allows the corresponding bit in the raw_status register to generate the intr1_sts interrupt. Read only.
0x34924 AIL_pe_0_EV1_Enable_Set wo — (1 of 1, stride 0)
  [21] pe_ee_ofifo_oflow_err — Sets the corresponding bit in the intr1_status register when set. Write only, self-clears.
  [19:16] pe_ee_cpri_cw_hypfm_oflow_err — Sets the corresponding bit in the intr1_status register when set. Write only, self-clears.
  [15:12] pe_ee_cpri_cw_hdlc_starve_err — Sets the corresponding bit in the intr1_status register when set. Write only, self-clears.
  [11:8] pe_ee_cpri_cw_hypfm_starve_err — Sets the corresponding bit in the intr1_status register when set. Write only, self-clears.
  [7:4] pe_ee_cpri_cw_4b5b_starve_err — Sets the corresponding bit in the intr1_status register when set. Write only, self-clears.
  [3:0] pe_ee_cpri_cw_null_starve_err — Sets the corresponding bit in the intr1_status register when set. Write only, self-clears.
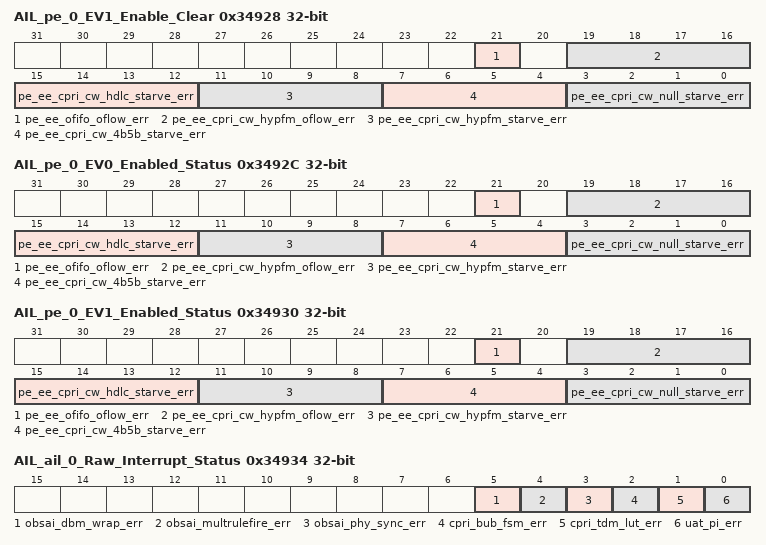
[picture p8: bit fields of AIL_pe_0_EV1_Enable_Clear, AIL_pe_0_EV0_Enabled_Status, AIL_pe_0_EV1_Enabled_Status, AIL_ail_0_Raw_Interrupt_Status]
0x34928 AIL_pe_0_EV1_Enable_Clear wo — (1 of 1, stride 0)
  [21] pe_ee_ofifo_oflow_err — Clears the corresponding bit in the intr1_status register when set. Write only, self-clears.
  [19:16] pe_ee_cpri_cw_hypfm_oflow_err — Clears the corresponding bit in the intr1_status register when set. Write only, self-clears.
  [15:12] pe_ee_cpri_cw_hdlc_starve_err — Clears the corresponding bit in the intr1_status register when set. Write only, self-clears.
  [11:8] pe_ee_cpri_cw_hypfm_starve_err — Clears the corresponding bit in the intr1_status register when set. Write only, self-clears.
  [7:4] pe_ee_cpri_cw_4b5b_starve_err — Clears the corresponding bit in the intr1_status register when set. Write only, self-clears.
  [3:0] pe_ee_cpri_cw_null_starve_err — Clears the corresponding bit in the intr1_status register when set. Write only, self-clears.
0x3492C AIL_pe_0_EV0_Enabled_Status — (1 of 1, stride 0)
  [21] pe_ee_ofifo_oflow_err — AND-ed raw_status bits with the corresponding bit in the enable_status register. Read only.
  [19:16] pe_ee_cpri_cw_hypfm_oflow_err — AND-ed raw_status bits with the corresponding bit in the enable_status register. Read only.
  [15:12] pe_ee_cpri_cw_hdlc_starve_err — AND-ed raw_status bits with the corresponding bit in the enable_status register. Read only.
  [11:8] pe_ee_cpri_cw_hypfm_starve_err — AND-ed raw_status bits with the corresponding bit in the enable_status register. Read only.
  [7:4] pe_ee_cpri_cw_4b5b_starve_err — AND-ed raw_status bits with the corresponding bit in the enable_status register. Read only.
  [3:0] pe_ee_cpri_cw_null_starve_err — AND-ed raw_status bits with the corresponding bit in the enable_status register. Read only.
0x34930 AIL_pe_0_EV1_Enabled_Status — (1 of 1, stride 0)
  [21] pe_ee_ofifo_oflow_err — AND-ed raw_status bits with the corresponding bit in the intr1_status register. Read only.
  [19:16] pe_ee_cpri_cw_hypfm_oflow_err — AND-ed raw_status bits with the corresponding bit in the intr1_status register. Read only.
  [15:12] pe_ee_cpri_cw_hdlc_starve_err — AND-ed raw_status bits with the corresponding bit in the intr1_status register. Read only.
  [11:8] pe_ee_cpri_cw_hypfm_starve_err — AND-ed raw_status bits with the corresponding bit in the intr1_status register. Read only.
  [7:4] pe_ee_cpri_cw_4b5b_starve_err — AND-ed raw_status bits with the corresponding bit in the intr1_status register. Read only.
  [3:0] pe_ee_cpri_cw_null_starve_err — AND-ed raw_status bits with the corresponding bit in the intr1_status register. Read only.
0x34934 AIL_ail_0_Raw_Interrupt_Status — (1 of 1, stride 0)
  [5] obsai_dbm_wrap_err — An OBSAI Transmission Rule (MOD or DBM) did not wrap back naturally on a PHY frame boundary. Likely a programming error of OBSAI rules, possibly rules rates which are incompatible with link rate
  [4] obsai_multrulefire_err — Multiple OBSAI rules fired simultaniously. Indicates a programming error of OBSAI rules.
  [3] obsai_phy_sync_err — The uAT indicated to the PE_SCH of an OBSAI PHY frame boundary, but OBSAI FSM did not predict a PHY frame boundary. Likely indicates a programming error of OBSAI PHY FSM. Also will trigger if uAT timing is changed while PE_SCH OBSAI PHY FSM is currently
  [2] cpri_bub_fsm_err — The bubble FSM did not wrap back to zero on a radio frame boundary. This is likely a programming error. In GSM, a radio frame boundary is 60ms.
  [1] cpri_tdm_lut_err — CPRI Channel TDM did not wrap back to start position prior to end of an iteration window (few GSM cases will legally cause this EE) Mostly likely cause is incorrect programming of TDM and Bubble insertion parameters.
  [0] uat_pi_err — UAT OBSAI PI error. PHY_RM PHY frame boundary detected outside programmed window specified by uat_pimax_cfg_pi_max_cfg (OBSAI defines Pi as reception time of PHY FB)
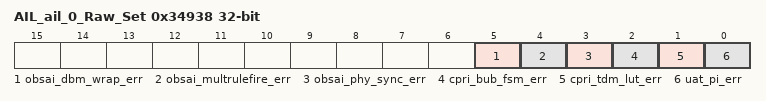
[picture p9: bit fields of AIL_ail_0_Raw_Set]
0x34938 AIL_ail_0_Raw_Set wo — (1 of 1, stride 0)
  [5] obsai_dbm_wrap_err — Sets the corresponding bit in the raw_status register when set. Write only, self-clears.
  [4] obsai_multrulefire_err — Sets the corresponding bit in the raw_status register when set. Write only, self-clears.
  [3] obsai_phy_sync_err — Sets the corresponding bit in the raw_status register when set. Write only, self-clears.
  [2] cpri_bub_fsm_err — Sets the corresponding bit in the raw_status register when set. Write only, self-clears.
  [1] cpri_tdm_lut_err — Sets the corresponding bit in the raw_status register when set. Write only, self-clears.
  [0] uat_pi_err — Sets the corresponding bit in the raw_status register when set. Write only, self-clears.
